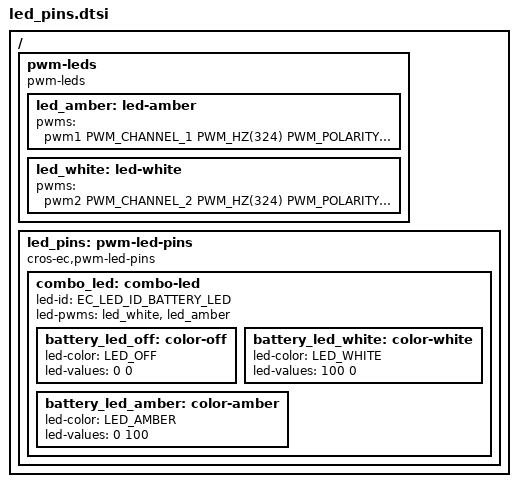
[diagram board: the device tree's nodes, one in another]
/* Copyright 2026 The ChromiumOS Authors
 * Use of this source code is governed by a BSD-style license that can be
 * found in the LICENSE file.
 */

 / {
	pwm-leds {
		compatible = "pwm-leds";
		/* NOTE: &pwm number needs same with channel number */
		led_amber: led-amber {
			pwms = <&pwm1 PWM_CHANNEL_1 PWM_HZ(324) PWM_POLARITY_INVERTED>;
		};
		led_white: led-white {
			pwms = <&pwm2 PWM_CHANNEL_2 PWM_HZ(324) PWM_POLARITY_INVERTED>;
		};
	};

	led_pins: pwm-led-pins {
		compatible = "cros-ec,pwm-led-pins";

		combo_led: combo-led {
			led-id = "EC_LED_ID_BATTERY_LED";
			led-pwms = <&led_white &led_amber>;
			battery_led_off: color-off {
				led-color = "LED_OFF";
				led-values = <0 0>;
			};

			battery_led_white: color-white {
				led-color = "LED_WHITE";
				led-values = <100 0>;
			};

			battery_led_amber: color-amber {
				led-color = "LED_AMBER";
				led-values = <0 100>;
			};
		};
	};
};
